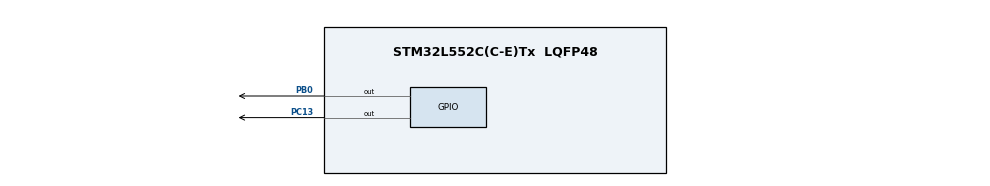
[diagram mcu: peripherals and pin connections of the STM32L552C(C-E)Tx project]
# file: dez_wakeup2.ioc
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Mcu.Family=STM32L5
Mcu.Name=STM32L552C(C-E)Tx
Mcu.Package=LQFP48
NVIC.PriorityGroup=NVIC_PRIORITYGROUP_3
NVIC.RTC_IRQn=true\:0\:0\:false\:false\:true\:true\:true\:true
PB0.Signal=GPIO_Output
PC13.Signal=GPIO_Output
ProjectManager.HeapSize=0x200
ProjectManager.StackSize=0x400
ProjectManager.TargetToolchain=STM32CubeIDE
RCC.HSE_VALUE=16000000
RCC.HSI48_VALUE=48000000
RCC.HSI_VALUE=16000000
RCC.LSE_VALUE=32768
RCC.MSI_VALUE=4000000
RCC.VCOOutputFreq_Value=32000000
RTC.WakeUpCounter-WakeUp=40960
VP_PWR_VS_DBSignals.Mode=DisableDeadBatterySignals
VP_PWR_VS_SECSignals.Mode=Security/Privilege
VP_RTC_VS_RTC_Activate.Mode=RTC_Enabled
VP_RTC_VS_RTC_WakeUp_intern.Mode=WakeUp
board=custom

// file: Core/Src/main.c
/* USER CODE BEGIN Header */
/**
  ******************************************************************************
  * @file           : main.c
  * @brief          : Main program body
  ******************************************************************************
  * @attention
  *
  * Copyright (c) 2025 STMicroelectronics.
  * All rights reserved.
  *
  * This software is licensed under terms that can be found in the LICENSE file
  * in the root directory of this software component.
  * If no LICENSE file comes with this software, it is provided AS-IS.
  *
  ******************************************************************************
  */
/* USER CODE END Header */
#include "main.h"

RTC_HandleTypeDef hrtc;

/* USER CODE BEGIN PV */
// Флаг для отслеживания пробуждения
volatile uint8_t wakeup_flag = 0;
/* USER CODE END PV */

void SystemClock_Config(void);
static void MX_GPIO_Init(void);
static void MX_RTC_Init(void);

int main(void)
{

  /* MCU Configuration--------------------------------------------------------*/

  /* Reset of all peripherals, Initializes the Flash interface and the Systick. */
  HAL_Init();

  /* Configure the system clock */
  SystemClock_Config();

  /* Initialize all configured peripherals */
  MX_GPIO_Init();
  MX_RTC_Init();
  /* USER CODE BEGIN 2 */

  // Включаем обработчик прерывания RTC WakeUp
  HAL_NVIC_SetPriority(RTC_IRQn, 0, 0);
  HAL_NVIC_EnableIRQ(RTC_IRQn);

  // Инициализируем пины как выключенные (сон)
  HAL_GPIO_WritePin(GPIOC, GPIO_PIN_13, GPIO_PIN_RESET);
  HAL_GPIO_WritePin(GPIOB, GPIO_PIN_0, GPIO_PIN_RESET);

  /* USER CODE END 2 */

  /* Infinite loop */
  while (1)
  {

    /* USER CODE BEGIN 3 */
    // Проверяем флаг пробуждения
    if(wakeup_flag)
    {
      // Сбрасываем флаг
      wakeup_flag = 0;

      // Включаем пины PC13 и PB0 на 5 секунд (пробуждение)
      HAL_GPIO_WritePin(GPIOC, GPIO_PIN_13, GPIO_PIN_SET);
      HAL_GPIO_WritePin(GPIOB, GPIO_PIN_0, GPIO_PIN_SET);

      // Ждем 5 секунд
      HAL_Delay(5000);

      // Выключаем пины (готовимся ко сну)
      HAL_GPIO_WritePin(GPIOC, GPIO_PIN_13, GPIO_PIN_RESET);
      HAL_GPIO_WritePin(GPIOB, GPIO_PIN_0, GPIO_PIN_RESET);

      // Переконфигурируем RTC WakeUp для 10 секунд сна
      HAL_RTCEx_DeactivateWakeUpTimer(&hrtc);
      if (HAL_RTCEx_SetWakeUpTimer_IT(&hrtc, 20479, RTC_WAKEUPCLOCK_RTCCLK_DIV16, 0) != HAL_OK)
      {
        Error_Handler();
      }
    }

    // Переходим в режим сна
    HAL_PWR_EnterSLEEPMode(PWR_MAINREGULATOR_ON, PWR_SLEEPENTRY_WFI);
  }
  /* USER CODE END 3 */
}

void SystemClock_Config(void)
{
  RCC_OscInitTypeDef RCC_OscInitStruct = {0};
  RCC_ClkInitTypeDef RCC_ClkInitStruct = {0};

  /** Configure the main internal regulator output voltage
  */
  if (HAL_PWREx_ControlVoltageScaling(PWR_REGULATOR_VOLTAGE_SCALE2) != HAL_OK)
  {
    Error_Handler();
  }

  /** Initializes the RCC Oscillators according to the specified parameters
  * in the RCC_OscInitTypeDef structure.
  */
  RCC_OscInitStruct.OscillatorType = RCC_OSCILLATORTYPE_LSI|RCC_OSCILLATORTYPE_MSI;
  RCC_OscInitStruct.LSIDiv = RCC_LSI_DIV1;
  RCC_OscInitStruct.LSIState = RCC_LSI_ON;
  RCC_OscInitStruct.MSIState = RCC_MSI_ON;
  RCC_OscInitStruct.MSICalibrationValue = RCC_MSICALIBRATION_DEFAULT;
  RCC_OscInitStruct.MSIClockRange = RCC_MSIRANGE_6;
  RCC_OscInitStruct.PLL.PLLState = RCC_PLL_NONE;
  if (HAL_RCC_OscConfig(&RCC_OscInitStruct) != HAL_OK)
  {
    Error_Handler();
  }

  /** Initializes the CPU, AHB and APB buses clocks
  */
  RCC_ClkInitStruct.ClockType = RCC_CLOCKTYPE_HCLK|RCC_CLOCKTYPE_SYSCLK
                              |RCC_CLOCKTYPE_PCLK1|RCC_CLOCKTYPE_PCLK2;
  RCC_ClkInitStruct.SYSCLKSource = RCC_SYSCLKSOURCE_MSI;
  RCC_ClkInitStruct.AHBCLKDivider = RCC_SYSCLK_DIV1;
  RCC_ClkInitStruct.APB1CLKDivider = RCC_HCLK_DIV1;
  RCC_ClkInitStruct.APB2CLKDivider = RCC_HCLK_DIV1;

  if (HAL_RCC_ClockConfig(&RCC_ClkInitStruct, FLASH_LATENCY_0) != HAL_OK)
  {
    Error_Handler();
  }
}

static void MX_RTC_Init(void)
{

  RTC_PrivilegeStateTypeDef privilegeState = {0};

  /** Initialize RTC Only
  */
  hrtc.Instance = RTC;
  hrtc.Init.HourFormat = RTC_HOURFORMAT_24;
  hrtc.Init.AsynchPrediv = 127;
  hrtc.Init.SynchPrediv = 255;
  hrtc.Init.OutPut = RTC_OUTPUT_DISABLE;
  hrtc.Init.OutPutRemap = RTC_OUTPUT_REMAP_NONE;
  hrtc.Init.OutPutPolarity = RTC_OUTPUT_POLARITY_HIGH;
  hrtc.Init.OutPutType = RTC_OUTPUT_TYPE_OPENDRAIN;
  hrtc.Init.OutPutPullUp = RTC_OUTPUT_PULLUP_NONE;
  if (HAL_RTC_Init(&hrtc) != HAL_OK)
  {
    Error_Handler();
  }
  privilegeState.rtcPrivilegeFull = RTC_PRIVILEGE_FULL_NO;
  privilegeState.backupRegisterPrivZone = RTC_PRIVILEGE_BKUP_ZONE_NONE;
  privilegeState.backupRegisterStartZone2 = RTC_BKP_DR0;
  privilegeState.backupRegisterStartZone3 = RTC_BKP_DR0;
  if (HAL_RTCEx_PrivilegeModeSet(&hrtc, &privilegeState) != HAL_OK)
  {
    Error_Handler();
  }

  /** Enable the WakeUp
  */
  // Расчет для 10 секунд: LSI = ~32.768 kHz, делитель 16 -> 2048 Гц
  // 2048 Гц * 10 сек = 20480 тиков. Вычитаем 1, так как счетчик с нуля.
  if (HAL_RTCEx_SetWakeUpTimer_IT(&hrtc, 20479, RTC_WAKEUPCLOCK_RTCCLK_DIV16, 0) != HAL_OK)
  {
    Error_Handler();
  }
}

static void MX_GPIO_Init(void)
{
  GPIO_InitTypeDef GPIO_InitStruct = {0};

  /* GPIO Ports Clock Enable */
  __HAL_RCC_GPIOC_CLK_ENABLE();
  __HAL_RCC_GPIOB_CLK_ENABLE();

  /*Configure GPIO pin Output Level */
  HAL_GPIO_WritePin(GPIOC, GPIO_PIN_13, GPIO_PIN_RESET);

  /*Configure GPIO pin Output Level */
  HAL_GPIO_WritePin(GPIOB, GPIO_PIN_0, GPIO_PIN_RESET);

  /*Configure GPIO pin : PC13 */
  GPIO_InitStruct.Pin = GPIO_PIN_13;
  GPIO_InitStruct.Mode = GPIO_MODE_OUTPUT_PP;
  GPIO_InitStruct.Pull = GPIO_NOPULL;
  GPIO_InitStruct.Speed = GPIO_SPEED_FREQ_LOW;
  HAL_GPIO_Init(GPIOC, &GPIO_InitStruct);

  /*Configure GPIO pin : PB0 */
  GPIO_InitStruct.Pin = GPIO_PIN_0;
  GPIO_InitStruct.Mode = GPIO_MODE_OUTPUT_PP;
  GPIO_InitStruct.Pull = GPIO_NOPULL;
  GPIO_InitStruct.Speed = GPIO_SPEED_FREQ_LOW;
  HAL_GPIO_Init(GPIOB, &GPIO_InitStruct);

}

/* USER CODE BEGIN 4 */
/**
  * @brief  Обработчик прерывания WakeUp Timer.
  * @retval None
  */
void HAL_RTCEx_WakeUpTimerEventCallback(RTC_HandleTypeDef *hrtc)
{
  // Устанавливаем флаг пробуждения
  wakeup_flag = 1;
}

/**
  * @brief  Обработчик прерывания RTC WakeUp.
  * @retval None
  */
void RTC_WKUP_IRQHandler(void)
{
  HAL_RTCEx_WakeUpTimerIRQHandler(&hrtc);
  __HAL_RTC_WAKEUPTIMER_EXTI_CLEAR_FLAG();
}
/* USER CODE END 4 */

void Error_Handler(void)
{
  __disable_irq();
  while (1)
  {
  }
}
